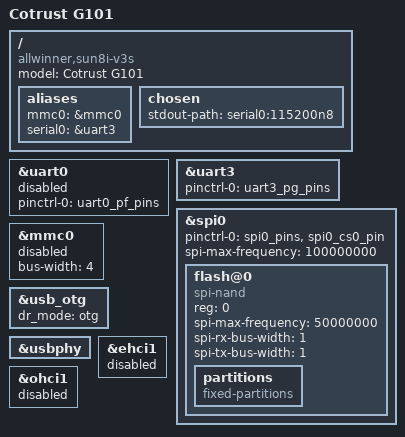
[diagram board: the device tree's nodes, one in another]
/*
 * Copyright (C) 2016 Icenowy Zheng <icenowy@aosc.xyz>
 *
 * This file is dual-licensed: you can use it either under the terms
 * of the GPL or the X11 license, at your option. Note that this dual
 * licensing only applies to this file, and not this project as a
 * whole.
 *
 *  a) This file is free software; you can redistribute it and/or
 *     modify it under the terms of the GNU General Public License as
 *     published by the Free Software Foundation; either version 2 of the
 *     License, or (at your option) any later version.
 *
 *     This file is distributed in the hope that it will be useful,
 *     but WITHOUT ANY WARRANTY; without even the implied warranty of
 *     MERCHANTABILITY or FITNESS FOR A PARTICULAR PURPOSE.  See the
 *     GNU General Public License for more details.
 *
 * Or, alternatively,
 *
 *  b) Permission is hereby granted, free of charge, to any person
 *     obtaining a copy of this software and associated documentation
 *     files (the "Software"), to deal in the Software without
 *     restriction, including without limitation the rights to use,
 *     copy, modify, merge, publish, distribute, sublicense, and/or
 *     sell copies of the Software, and to permit persons to whom the
 *     Software is furnished to do so, subject to the following
 *     conditions:
 *
 *     The above copyright notice and this permission notice shall be
 *     included in all copies or substantial portions of the Software.
 *
 *     THE SOFTWARE IS PROVIDED "AS IS", WITHOUT WARRANTY OF ANY KIND,
 *     EXPRESS OR IMPLIED, INCLUDING BUT NOT LIMITED TO THE WARRANTIES
 *     OF MERCHANTABILITY, FITNESS FOR A PARTICULAR PURPOSE AND
 *     NONINFRINGEMENT. IN NO EVENT SHALL THE AUTHORS OR COPYRIGHT
 *     HOLDERS BE LIABLE FOR ANY CLAIM, DAMAGES OR OTHER LIABILITY,
 *     WHETHER IN AN ACTION OF CONTRACT, TORT OR OTHERWISE, ARISING
 *     FROM, OUT OF OR IN CONNECTION WITH THE SOFTWARE OR THE USE OR
 *     OTHER DEALINGS IN THE SOFTWARE.
 */

/dts-v1/;
#include "sun8i-t113.dtsi"
#include <dt-bindings/gpio/gpio.h>

/ {
	model = "Cotrust G101";
	compatible = "allwinner,sun8i-v3s";

	aliases {
        mmc0 = &mmc0;
        serial0 = &uart3;
	};

	chosen {
        stdout-path = "serial0:115200n8";
	};

};

&uart0 {
	pinctrl-0 = <&uart0_pf_pins>;
	pinctrl-names = "default";
	status = "disabled";
};

&uart3 {
	pinctrl-0 = <&uart3_pg_pins>;
	pinctrl-names = "default";
	status = "okay";
};

&spi0  {
	status = "okay";
	pinctrl-names = "default";
	pinctrl-0 = <&spi0_pins>, <&spi0_cs0_pin>;
	spi-max-frequency = <100000000>;

 	flash@0 {
                 compatible = "spi-nand";
                 reg = <0>;
                 spi-max-frequency = <50000000>;
                 spi-rx-bus-width = <1>;
                 spi-tx-bus-width = <1>;

                 partitions {
                         compatible = "fixed-partitions";
                         #address-cells = <1>;
                         #size-cells = <1>;
		};
         };
};

&mmc0 {
	bus-width = <4>;
	status = "disabled";
};

&usb_otg {
	dr_mode = "otg";
	status = "okay";
};

&usbphy {
	status = "okay";
};

&ehci1 {
    status = "disable";
};

&ohci1 {
    status = "disable";
};
